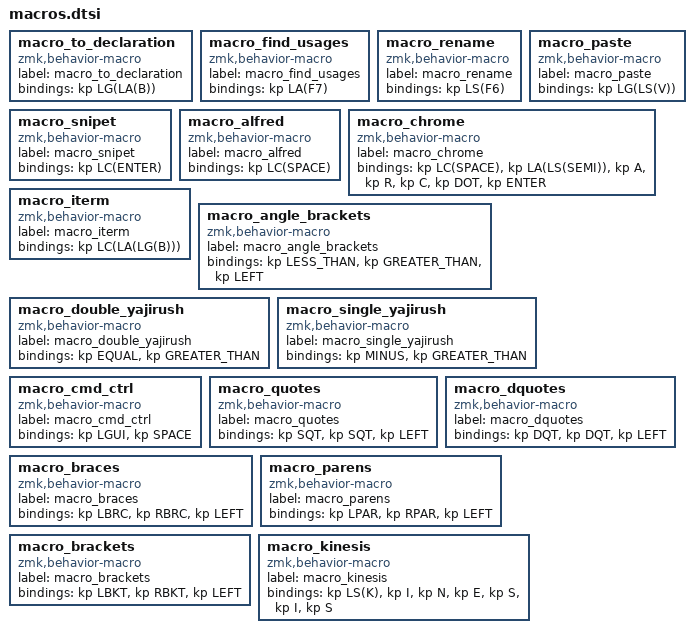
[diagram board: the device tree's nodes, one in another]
macro_to_declaration: macro_to_declaration{
compatible = "zmk,behavior-macro";
label = "macro_to_declaration";
#binding-cells = <0>;
bindings = <&kp LG(LA(B))>;
};
macro_find_usages: macro_find_usages{
compatible = "zmk,behavior-macro";
label = "macro_find_usages";
#binding-cells = <0>;
bindings = <&kp LA(F7)>;
};
macro_rename: macro_rename{
compatible = "zmk,behavior-macro";
label = "macro_rename";
#binding-cells = <0>;
bindings = <&kp LS(F6)>;
};
macro_paste: macro_paste{
compatible = "zmk,behavior-macro";
label = "macro_paste";
#binding-cells = <0>;
bindings = <&kp LG(LS(V))>;
};
macro_snipet: macro_snipet{
compatible = "zmk,behavior-macro";
label = "macro_snipet";
#binding-cells = <0>;
bindings = <&kp LC(ENTER)>;
};
macro_alfred: macro_alfred{
compatible = "zmk,behavior-macro";
label = "macro_alfred";
#binding-cells = <0>;
bindings = <&kp LC(SPACE)>;
};
macro_chrome: macro_chrome{
compatible = "zmk,behavior-macro";
label = "macro_chrome";
#binding-cells = <0>;
bindings = <&kp LC(SPACE)>, <&kp LA(LS(SEMI))>, <&kp A>, <&kp R>, <&kp C>, <&kp DOT>, <&kp ENTER>;
};
macro_iterm: macro_iterm{
compatible = "zmk,behavior-macro";
label = "macro_iterm";
#binding-cells = <0>;
bindings = <&kp LC(LA(LG(B)))>;
};
macro_angle_brackets: macro_angle_brackets{
compatible = "zmk,behavior-macro";
label = "macro_angle_brackets";
#binding-cells = <0>;
bindings = <&kp LESS_THAN>, <&kp GREATER_THAN>, <&kp LEFT>;
};
macro_double_yajirush: macro_double_yajirush{
compatible = "zmk,behavior-macro";
label = "macro_double_yajirush";
#binding-cells = <0>;
bindings = <&kp EQUAL>, <&kp GREATER_THAN>;
};
macro_single_yajirush: macro_single_yajirush{
compatible = "zmk,behavior-macro";
label = "macro_single_yajirush";
#binding-cells = <0>;
bindings = <&kp MINUS>, <&kp GREATER_THAN>;
};
macro_cmd_ctrl: macro_cmd_ctrl{
compatible = "zmk,behavior-macro";
label = "macro_cmd_ctrl";
#binding-cells = <0>;
bindings = <&kp LGUI>, <&kp SPACE>;
};
macro_quotes: macro_quotes{
compatible = "zmk,behavior-macro";
label = "macro_quotes";
#binding-cells = <0>;
bindings = <&kp SQT>, <&kp SQT>, <&kp LEFT>;
};
macro_dquotes: macro_dquotes{
compatible = "zmk,behavior-macro";
label = "macro_dquotes";
#binding-cells = <0>;
bindings = <&kp DQT>, <&kp DQT>, <&kp LEFT>;
};
macro_braces: macro_braces{
compatible = "zmk,behavior-macro";
label = "macro_braces";
#binding-cells = <0>;
bindings = <&kp LBRC>, <&kp RBRC>, <&kp LEFT>;
};
macro_parens: macro_parens{
compatible = "zmk,behavior-macro";
label = "macro_parens";
#binding-cells = <0>;
bindings = <&kp LPAR>, <&kp RPAR>, <&kp LEFT>;
};
macro_brackets: macro_brackets{
compatible = "zmk,behavior-macro";
label = "macro_brackets";
#binding-cells = <0>;
bindings = <&kp LBKT>, <&kp RBKT>, <&kp LEFT>;
};
macro_kinesis: macro_kinesis{
compatible = "zmk,behavior-macro";
label = "macro_kinesis";
#binding-cells = <0>;
bindings = <&kp LS(K)>, <&kp I>, <&kp N>, <&kp E>, <&kp S>, <&kp I>, <&kp S>;
};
